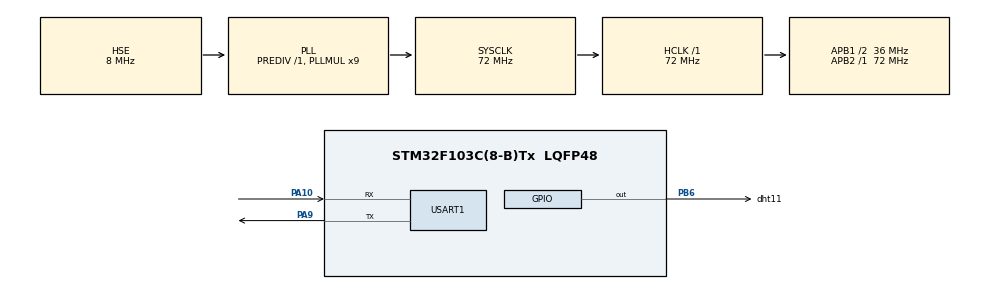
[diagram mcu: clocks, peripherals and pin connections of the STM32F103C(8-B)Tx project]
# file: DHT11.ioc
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Mcu.Family=STM32F1
Mcu.Name=STM32F103C(8-B)Tx
Mcu.Package=LQFP48
NVIC.PriorityGroup=NVIC_PRIORITYGROUP_4
PA10.Mode=Asynchronous
PA10.Signal=USART1_RX
PA13.Mode=Serial_Wire
PA13.Signal=SYS_JTMS-SWDIO
PA14.Mode=Serial_Wire
PA14.Signal=SYS_JTCK-SWCLK
PA9.Mode=Asynchronous
PA9.Signal=USART1_TX
PB6.GPIO_Label=dht11
PB6.Signal=GPIO_Output
PD0-OSC_IN.Mode=HSE-External-Oscillator
PD0-OSC_IN.Signal=RCC_OSC_IN
PD1-OSC_OUT.Mode=HSE-External-Oscillator
PD1-OSC_OUT.Signal=RCC_OSC_OUT
ProjectManager.HeapSize=0x200
ProjectManager.StackSize=0x400
ProjectManager.TargetToolchain=MDK-ARM V5
RCC.AHBFreq_Value=72000000
RCC.APB1CLKDivider=RCC_HCLK_DIV2
RCC.APB1Freq_Value=36000000
RCC.APB1TimFreq_Value=72000000
RCC.APB2Freq_Value=72000000
RCC.APB2TimFreq_Value=72000000
RCC.HCLKFreq_Value=72000000
RCC.PLLMUL=RCC_PLL_MUL9
RCC.PLLSourceVirtual=RCC_PLLSOURCE_HSE
RCC.SYSCLKFreq_VALUE=72000000
RCC.SYSCLKSource=RCC_SYSCLKSOURCE_PLLCLK
RCC.USBFreq_Value=72000000
USART1.VirtualMode=VM_ASYNC
board=DHT11

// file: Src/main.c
/**
  ******************************************************************************
  * @file           : main.c
  * @brief          : Main program body
  ******************************************************************************
  ** This notice applies to any and all portions of this file
  * that are not between comment pairs USER CODE BEGIN and
  * USER CODE END. Other portions of this file, whether
  * inserted by the user or by software development tools
  * are owned by their respective copyright owners.
  *
  * COPYRIGHT(c) 2020 STMicroelectronics
  *
  * Redistribution and use in source and binary forms, with or without modification,
  * are permitted provided that the following conditions are met:
  *   1. Redistributions of source code must retain the above copyright notice,
  *      this list of conditions and the following disclaimer.
  *   2. Redistributions in binary form must reproduce the above copyright notice,
  *      this list of conditions and the following disclaimer in the documentation
  *      and/or other materials provided with the distribution.
  *   3. Neither the name of STMicroelectronics nor the names of its contributors
  *      may be used to endorse or promote products derived from this software
  *      without specific prior written permission.
  *
  * THIS SOFTWARE IS PROVIDED BY THE COPYRIGHT HOLDERS AND CONTRIBUTORS "AS IS"
  * AND ANY EXPRESS OR IMPLIED WARRANTIES, INCLUDING, BUT NOT LIMITED TO, THE
  * IMPLIED WARRANTIES OF MERCHANTABILITY AND FITNESS FOR A PARTICULAR PURPOSE ARE
  * DISCLAIMED. IN NO EVENT SHALL THE COPYRIGHT HOLDER OR CONTRIBUTORS BE LIABLE
  * FOR ANY DIRECT, INDIRECT, INCIDENTAL, SPECIAL, EXEMPLARY, OR CONSEQUENTIAL
  * DAMAGES (INCLUDING, BUT NOT LIMITED TO, PROCUREMENT OF SUBSTITUTE GOODS OR
  * SERVICES; LOSS OF USE, DATA, OR PROFITS; OR BUSINESS INTERRUPTION) HOWEVER
  * CAUSED AND ON ANY THEORY OF LIABILITY, WHETHER IN CONTRACT, STRICT LIABILITY,
  * OR TORT (INCLUDING NEGLIGENCE OR OTHERWISE) ARISING IN ANY WAY OUT OF THE USE
  * OF THIS SOFTWARE, EVEN IF ADVISED OF THE POSSIBILITY OF SUCH DAMAGE.
  *
  ******************************************************************************
  */
#include "main.h"
#include "stm32f1xx_hal.h"

/* USER CODE BEGIN Includes */

#include "dwt_delay.h"

/* USER CODE END Includes */

UART_HandleTypeDef huart1;

/* USER CODE BEGIN PV */
/* Private variables ---------------------------------------------------------*/
GPIO_InitTypeDef GPIO_InitStruct;
uint8_t hum_int,hum_dec,temp_int,temp_dec,check_sum,counter1 = 0,counter2 = 0;
/* USER CODE END PV */

void SystemClock_Config(void);
static void MX_GPIO_Init(void);
static void MX_USART1_UART_Init(void);

/* USER CODE BEGIN PFP */
/* Private function prototypes -----------------------------------------------*/

/* USER CODE END PFP */

/* USER CODE BEGIN 0 */

void set_output_dht()
{
  GPIO_InitStruct.Pin = dht11_Pin;
  GPIO_InitStruct.Mode = GPIO_MODE_OUTPUT_PP;
  GPIO_InitStruct.Speed = GPIO_SPEED_FREQ_LOW;
  HAL_GPIO_Init(dht11_GPIO_Port, &GPIO_InitStruct);
}

void set_input_dht()
{
  GPIO_InitStruct.Pin = dht11_Pin;
  GPIO_InitStruct.Mode = GPIO_MODE_INPUT;
  GPIO_InitStruct.Pull = GPIO_NOPULL;
  HAL_GPIO_Init(dht11_GPIO_Port, &GPIO_InitStruct);
}

void start_dht()
{
	set_output_dht();
	HAL_GPIO_WritePin(dht11_GPIO_Port,dht11_Pin,0);
	DWT_Delay(18000);
	HAL_GPIO_WritePin(dht11_GPIO_Port,dht11_Pin,1);
	set_input_dht();
	DWT_Delay(50);
	while(!HAL_GPIO_ReadPin(dht11_GPIO_Port,dht11_Pin));
	while(HAL_GPIO_ReadPin(dht11_GPIO_Port,dht11_Pin));
}

uint8_t read_dht()
{
	uint8_t data,i;
	for(i = 0;i<8;i++)
	{
		while(!(HAL_GPIO_ReadPin(dht11_GPIO_Port,dht11_Pin)));
		DWT_Delay(40);
		if(HAL_GPIO_ReadPin(dht11_GPIO_Port,dht11_Pin))
		{
			data |= 1<<(7-i);
		}
		else
		{
			data &= ~(1<<(7-i));
		}
		while(HAL_GPIO_ReadPin(dht11_GPIO_Port,dht11_Pin));
	}
	return data;
}

#ifdef __GNUC__
/* With GCC/RAISONANCE, small printf (option LD Linker->Libraries->Small printf
   set to 'Yes') calls __io_putchar() */
#define PUTCHAR_PROTOTYPE int __io_putchar(int ch)
#else
#define PUTCHAR_PROTOTYPE int fputc(int ch, FILE *f)
#endif /* __GNUC__ */
PUTCHAR_PROTOTYPE
{
  /* Place your implementation of fputc here */
  /* e.g. write a character to the USART1 and Loop until the end of transmission */
  HAL_UART_Transmit(&huart1, (uint8_t *)&ch, 1, 0xFFFF);

  return ch;
}

/* USER CODE END 0 */

int main(void)
{

  /* MCU Configuration----------------------------------------------------------*/

  /* Reset of all peripherals, Initializes the Flash interface and the Systick. */
  HAL_Init();

  /* Configure the system clock */
  SystemClock_Config();

  /* Initialize all configured peripherals */
  MX_GPIO_Init();
  MX_USART1_UART_Init();
  /* USER CODE BEGIN 2 */
	DWT_Init();

  /* USER CODE END 2 */

  /* Infinite loop */
  /* USER CODE BEGIN WHILE */
  while (1)
  {
		counter1++;
		start_dht();
		hum_int = read_dht();
		hum_dec = read_dht();
		temp_int = read_dht();
		temp_dec = read_dht();
		check_sum = read_dht();
		counter2++;
		printf("%d\n",hum_int);
		printf("%d\n",hum_dec);
		printf("%d\n",temp_int);
		printf("%d\n",temp_dec);
		printf("%d\n",check_sum);
		HAL_Delay(500);

  /* USER CODE END WHILE */

  }

}

void SystemClock_Config(void)
{

  RCC_OscInitTypeDef RCC_OscInitStruct;
  RCC_ClkInitTypeDef RCC_ClkInitStruct;

    /**Initializes the CPU, AHB and APB busses clocks
    */
  RCC_OscInitStruct.OscillatorType = RCC_OSCILLATORTYPE_HSE;
  RCC_OscInitStruct.HSEState = RCC_HSE_ON;
  RCC_OscInitStruct.HSEPredivValue = RCC_HSE_PREDIV_DIV1;
  RCC_OscInitStruct.HSIState = RCC_HSI_ON;
  RCC_OscInitStruct.PLL.PLLState = RCC_PLL_ON;
  RCC_OscInitStruct.PLL.PLLSource = RCC_PLLSOURCE_HSE;
  RCC_OscInitStruct.PLL.PLLMUL = RCC_PLL_MUL9;
  if (HAL_RCC_OscConfig(&RCC_OscInitStruct) != HAL_OK)
  {
    _Error_Handler(__FILE__, __LINE__);
  }

    /**Initializes the CPU, AHB and APB busses clocks
    */
  RCC_ClkInitStruct.ClockType = RCC_CLOCKTYPE_HCLK|RCC_CLOCKTYPE_SYSCLK
                              |RCC_CLOCKTYPE_PCLK1|RCC_CLOCKTYPE_PCLK2;
  RCC_ClkInitStruct.SYSCLKSource = RCC_SYSCLKSOURCE_PLLCLK;
  RCC_ClkInitStruct.AHBCLKDivider = RCC_SYSCLK_DIV1;
  RCC_ClkInitStruct.APB1CLKDivider = RCC_HCLK_DIV2;
  RCC_ClkInitStruct.APB2CLKDivider = RCC_HCLK_DIV1;

  if (HAL_RCC_ClockConfig(&RCC_ClkInitStruct, FLASH_LATENCY_2) != HAL_OK)
  {
    _Error_Handler(__FILE__, __LINE__);
  }

    /**Configure the Systick interrupt time
    */
  HAL_SYSTICK_Config(HAL_RCC_GetHCLKFreq()/1000);

    /**Configure the Systick
    */
  HAL_SYSTICK_CLKSourceConfig(SYSTICK_CLKSOURCE_HCLK);

  /* SysTick_IRQn interrupt configuration */
  HAL_NVIC_SetPriority(SysTick_IRQn, 0, 0);
}

/* USART1 init function */
static void MX_USART1_UART_Init(void)
{

  huart1.Instance = USART1;
  huart1.Init.BaudRate = 115200;
  huart1.Init.WordLength = UART_WORDLENGTH_8B;
  huart1.Init.StopBits = UART_STOPBITS_1;
  huart1.Init.Parity = UART_PARITY_NONE;
  huart1.Init.Mode = UART_MODE_TX_RX;
  huart1.Init.HwFlowCtl = UART_HWCONTROL_NONE;
  huart1.Init.OverSampling = UART_OVERSAMPLING_16;
  if (HAL_UART_Init(&huart1) != HAL_OK)
  {
    _Error_Handler(__FILE__, __LINE__);
  }

}

/** Configure pins as
        * Analog
        * Input
        * Output
        * EVENT_OUT
        * EXTI
*/
static void MX_GPIO_Init(void)
{

  /* GPIO Ports Clock Enable */
  __HAL_RCC_GPIOD_CLK_ENABLE();
  __HAL_RCC_GPIOA_CLK_ENABLE();
  __HAL_RCC_GPIOB_CLK_ENABLE();
}

void _Error_Handler(char *file, int line)
{
  while(1)
  {
  }
}

/************************ (C) COPYRIGHT STMicroelectronics *****END OF FILE****/
